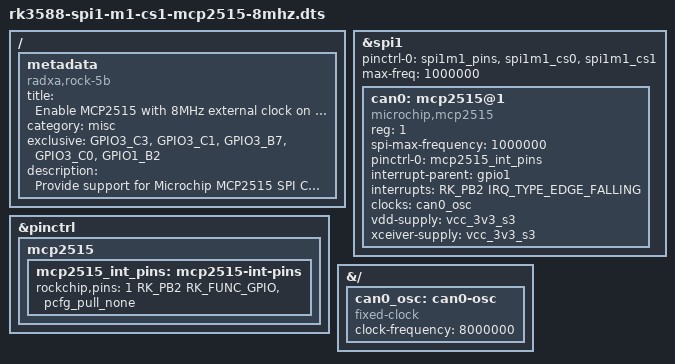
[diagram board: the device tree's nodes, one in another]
/dts-v1/;
/plugin/;

#include <dt-bindings/gpio/gpio.h>
#include <dt-bindings/pinctrl/rockchip.h>
#include <dt-bindings/interrupt-controller/irq.h>

/ {
	metadata {
		title = "Enable MCP2515 with 8MHz external clock on SPI1-M1 over CS1";
		compatible = "radxa,rock-5b", "radxa,rock-5b-plus", "radxa,rock-5t";
		category = "misc";
		exclusive = "GPIO3_C3", "GPIO3_C1", "GPIO3_B7", "GPIO3_C0", "GPIO1_B2";
		description = "Provide support for Microchip MCP2515 SPI CAN controller.
Assumes 8MHz external clock.
Uses Pin 19 (GPIOI1_B2) for INT.";
	};
};

&spi1 {
	status = "okay";
	pinctrl-names = "default";
	pinctrl-0 = <&spi1m1_pins &spi1m1_cs0 &spi1m1_cs1>;
	#address-cells = <1>;
	#size-cells = <0>;
	max-freq = <1000000>;

	can0: mcp2515@1 {
		status = "okay";
		compatible = "microchip,mcp2515";
		reg = <1>;
		spi-max-frequency = <1000000>;

		pinctrl-names = "default";
		pinctrl-0 = <&mcp2515_int_pins>;

		interrupt-parent = <&gpio1>;
		interrupts = <RK_PB2 IRQ_TYPE_EDGE_FALLING>;

		clocks = <&can0_osc>;
		vdd-supply = <&vcc_3v3_s3>;
		xceiver-supply = <&vcc_3v3_s3>;
	};
};

&pinctrl {
	mcp2515 {
		mcp2515_int_pins: mcp2515-int-pins {
			rockchip,pins = <1 RK_PB2 RK_FUNC_GPIO &pcfg_pull_none>;
		};
	};
};

&{/} {
	can0_osc: can0-osc {
		compatible = "fixed-clock";
		#clock-cells = <0>;
		clock-frequency  = <8000000>;
	};
};
